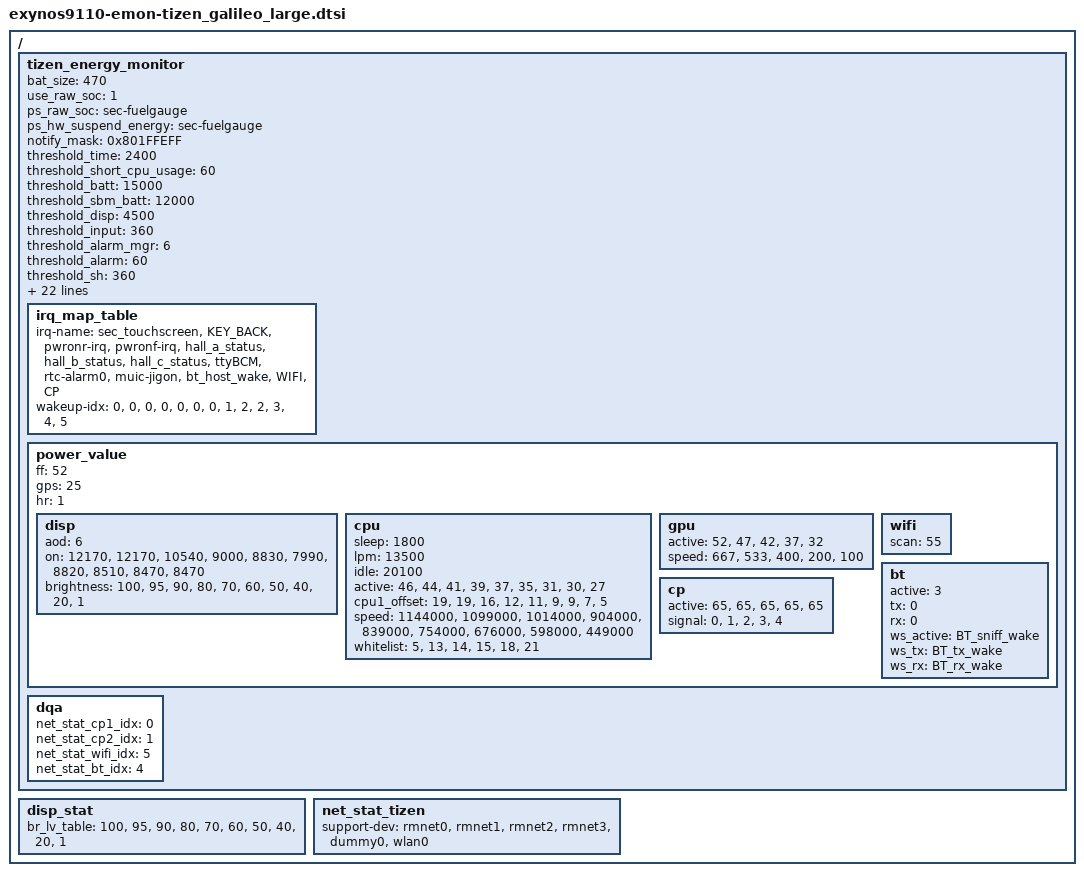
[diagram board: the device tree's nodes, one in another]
/*
 * Tizen Energy Monitor device tree source
 *
 * Copyright (c) 2017 Samsung Electronics Co., Ltd.
 *		http://www.samsung.com
 *
 * This program is free software; you can redistribute it and/or modify
 * it under the terms of the GNU General Public License version 2 as
 * published by the Free Software Foundation.
 */

/ {
	tizen_energy_monitor {
		bat_size = <470>;	/* 470 mAh */

		use_raw_soc = <1>;			/* battery support raw soc */
		ps_raw_soc = "sec-fuelgauge";		/* power supply for raw soc */
		ps_hw_suspend_energy = "sec-fuelgauge";		/* power supply for hw suspend energy */

		notify_mask = <0x801FFEFF>; /* a setting that controls wheather emon penalty notification can be processed or not */
		threshold_time = <2400>;		/* sec */
		threshold_short_cpu_usage = <60>;		/* sec */
		threshold_batt = <15000>;		/* uA */
		threshold_sbm_batt = <12000>;	/* uA */
		threshold_disp = <4500>;		/* uAh */
		threshold_input = <360>;		/* count */
		threshold_alarm_mgr = <6>;		/* count */
		threshold_alarm = <60>;		/* count */
		threshold_sh = <360>;		/* count */
		threshold_sh_wristup = <40>;		/* count */
		threshold_gps = <500>;		/* %% */
		threshold_lbs = <0>;			/* %% */
		threshold_cpuidle = <100>;		/* %% */
		threshold_cpu = <13200>;	/* uAh */
		threshold_gpu = <500>;	/* %% */
		threshold_ws = <500>;			/* %% */
		threshold_slwl = <500>;		/* %% */
		threshold_suspend_fail = <120>;		/* Threshold in count for generating fast battery drain event when there is a lot of suspend fail. */
		threshold_sid = <4700>;	/* uAh */
		threshold_pid = <500>;	/* Threshold in %% for generating fast battery drain event when bg processes has abnormal high cpu usage */
		threshold_booting_offset = <25000>;	/* uA */
		threshold_log_offset = <500>;	/* uA per MB */

		/* Threshold in count for generating fr event */
		threshold_fr_wakeup = <500>, <500>, <500>, <1000>, <1000>, <1000>, <2000>, <500>, <1000>, <0>, <0>;
		threshold_fr_suspend_fail = <300>;
		threshold_fr_suspend_failed_freeze = <200>;
		threshold_fr_suspend_failed_prepare = <300>;
		threshold_fr_suspend_failed_suspend = <300>;
		threshold_fr_suspend_failed_suspend_late = <300>;
		threshold_fr_suspend_failed_suspend_noirq = <300>;
		threshold_fr_suspend_success = <400>;

		irq_map_table {
			irq-name = "sec_touchscreen",	/* wakeup-idx = 0 */
				  "KEY_BACK",			/* wakeup-idx = 0 */
				  "pwronr-irq",			/* wakeup-idx = 0 */
				  "pwronf-irq",				/* wakeup-idx = 0 */
				  "hall_a_status",			/* wakeup-idx = 0 */
				  "hall_b_status",			/* wakeup-idx = 0 */
				  "hall_c_status",			/* wakeup-idx = 0 */
				  "ttyBCM",				/* wakeup-idx = 1 */
				  "rtc-alarm0",			/* wakeup-idx = 2 */
				  "muic-jigon",			/* wakeup-idx = 2 */
				  "bt_host_wake",			/* wakeup-idx = 3 */
				  "WIFI",					/* wakeup-idx = 4 */
				  "CP";					/* wakeup-idx = 5 */

			wakeup-idx = <0>,  <0>,  <0>,  <0>,  <0>,  <0>,  <0>,  <1>,  <2>,  <2>,  <3>,  <4>, <5>;
		};

		power_value {
			ff = <52>;
			gps = <25>;
			hr = <1>;

			disp {
				aod = <6>;
				on = <12170>, <12170>, <10540>, <9000>, <8830>, <7990>, <8820>, <8510>, <8470>, <8470>;
				brightness = <100>, <95>, <90>, <80>, <70>, <60>, <50>, <40>, <20>, <1>;
			};

			cpu {
				sleep = <1800>;
				lpm = <13500>;
				idle = <20100>;
				active = <46>, <44>, <41>, <39>, <37>, <35>, <31>, <30>, <27>;
				cpu1_offset = <19>, <19>, <16>, <12>, <11>, <9>, <9>, <7>, <5>;
				speed = <1144000>, <1099000>, <1014000>, <904000>, <839000>, <754000>, <676000>, <598000>, <449000>;
				whitelist = <5>, <13>, <14>, <15>, <18>, <21>;
			};

			gpu {
				active = <52>,  <47>,  <42>,  <37>,  <32>;
				speed = <667>,  <533>,  <400>,  <200>,  <100>;
			};

			wifi {
				scan = <55>;
			};

			bt {
				active = <3>;
				tx = <0>;
				rx = <0>;
				ws_active = "BT_sniff_wake";
				ws_tx = "BT_tx_wake";
				ws_rx = "BT_rx_wake";
			};

			cp {
				active = <65>,  <65>,  <65>,  <65>,  <65>;
				signal = <0>,  <1>,  <2>,  <3>,  <4>;
			};
		};

		dqa {
			net_stat_cp1_idx = <0>;
			net_stat_cp2_idx = <1>;
			net_stat_wifi_idx = <5>;
			net_stat_bt_idx = <4>;
		};
	};

	disp_stat {
		br_lv_table = <100>, <95>, <90>, <80>, <70>, <60>, <50>, <40>, <20>, <1>;
	};

	net_stat_tizen {
		support-dev = "rmnet0",
			  "rmnet1",
			  "rmnet2",
			  "rmnet3",
			  "dummy0",
			  "wlan0";
	};
};
